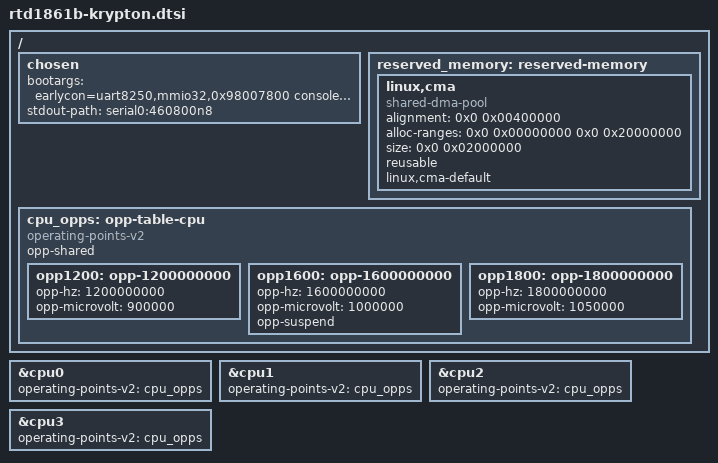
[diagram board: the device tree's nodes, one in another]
// SPDX-License-Identifier: (GPL-2.0-or-later OR BSD-2-Clause)
/*
 * Realtek RTD1861B Krypton EVB
 *
 * Copyright (c) 2024 Realtek Semiconductor Corp.
 */

/dts-v1/;

#include "rtd1861.dtsi"

/ {
	chosen {
		bootargs = "earlycon=uart8250,mmio32,0x98007800 console=ttyS0,460800 8250.nr_uarts=1
			    8250.share_irqs=1 init=/init loglevel=8 max_loop=64 loop.max_part=7
			    firmware_class.path=/vendor/firmware/,/vendor/av_fw";
		stdout-path = "serial0:460800n8";
	};

	reserved_memory: reserved-memory {
		#address-cells = <2>;
		#size-cells = <2>;
		ranges;

		linux,cma {
			compatible = "shared-dma-pool";
			alignment = <0x0 0x00400000>;
			alloc-ranges = <0x0 0x00000000 0x0 0x20000000>;
			size = <0x0 0x02000000>;
			reusable;
			linux,cma-default;
		};
	};

	cpu_opps: opp-table-cpu {
		compatible = "operating-points-v2";
		opp-shared;

		opp1200: opp-1200000000 {
			opp-hz = /bits/ 64 <1200000000>;
			opp-microvolt = <900000>;
			status = "okay";
		};

		opp1600: opp-1600000000 {
			opp-hz = /bits/ 64 <1600000000>;
			opp-microvolt = <1000000>;
			opp-suspend;
			status = "okay";
		};

		opp1800: opp-1800000000 {
			opp-hz = /bits/ 64 <1800000000>;
			opp-microvolt = <1050000>;
			status = "okay";
		};
	};
};

&cpu0 {
	operating-points-v2 = <&cpu_opps>;
	#cooling-cells = <2>;
};

&cpu1 {
	operating-points-v2 = <&cpu_opps>;
	#cooling-cells = <2>;
};

&cpu2 {
	operating-points-v2 = <&cpu_opps>;
	#cooling-cells = <2>;
};

&cpu3 {
	operating-points-v2 = <&cpu_opps>;
	#cooling-cells = <2>;
};

